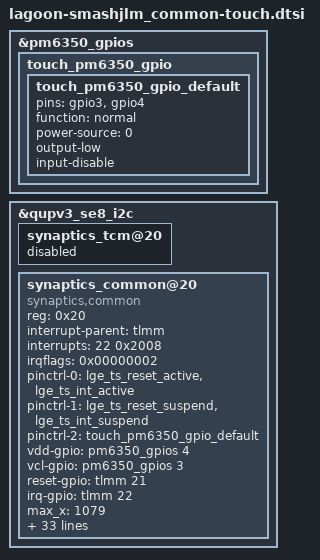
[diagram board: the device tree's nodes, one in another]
// SPDX-License-Identifier: GPL-2.0-only
/*
 * Copyright (c) 2018-2019, The Linux Foundation. All rights reserved.
 */

&pm6350_gpios {
	touch_pm6350_gpio{
		touch_pm6350_gpio_default: touch_pm6350_gpio_default {
			pins = "gpio3", "gpio4";
			function = "normal";
			power-source = <0>;
			output-low;
			input-disable;
		};
	};
};

&qupv3_se8_i2c {

	status = "okay";

	synaptics_tcm@20 {
		status = "disabled";
	};

	synaptics_common@20 {
		status = "ok";
		compatible = "synaptics,common";

		reg = <0x20>;
		interrupt-parent = <&tlmm>;
		interrupts = <22 0x2008>;
		irqflags = <0x00000002>;      // Falling-Edge Trigger
		//irqflags = <0x00000008>;        // Low-Level Trigger

		pinctrl-names = "touch_pin_active", "touch_pin_sleep", "touch_pm6350_gpio_default";
		pinctrl-0 = <&lge_ts_reset_active &lge_ts_int_active>;
		pinctrl-1 = <&lge_ts_reset_suspend &lge_ts_int_suspend>;
		pinctrl-2 = <&touch_pm6350_gpio_default>;

		vdd-gpio = <&pm6350_gpios 4 0x00>;
		vcl-gpio = <&pm6350_gpios 3 0x00>;
		reset-gpio = <&tlmm 21 0x00>;
		irq-gpio = <&tlmm 22 0x2008>;

		/* Caps */
		max_x = <1079>;
		max_y = <2339>;
		max_pressure = <0xff>;
		max_width_major = <2339>;
		max_width_minor = <2339>;
		max_orientation = <90>;
		max_id = <10>;
		hw_reset_delay = <200>;
		sw_reset_delay = <200>;

		/* Role */
		use_lpwg = <1>;
		use_lpwg_test = <1>;
		hide_coordinate = <1>;
		use_film_status = <1>;
		use_synaptics_touchcomm = <1>;

		/* Firmware */
		fw_image = "touch/smashjlm/main/tianma/PLG675-V0.25-PR3106505-s3618_DS6_60064119.img",
			 "touch/smashjlm/main/tovis/PLG674-V0.05-PR3005749-s3706b_BLV86_DS5.10.81.2_20064105.img",
			 "touch/smashjlm/main/tovis/PLG680-V1.05-PR3151223-s3706b_BLV86_DS5.10.81.2_20064185.img";
		panel_spec = "touch/smashjlm/main/tovis/mh2lm_synaptics_limit.txt";
		panel_spec_mfts_folder = "touch/smashjlm/main/tovis/mh2lm_synaptics_limit_mfts.txt";

		/* Performance Test */
		use_perf_test = <1>;
		test_delay = <8>;
		test_pressure = <50>;
		test_width = <100>;
		click_test_x = <180>;
		click_test_y = <756>;
		v_drag_test_x = <144>;
		v_drag_test_start_y = <1971>;
		v_drag_test_end_y = <1148>;
		h_drag_test_start_x = <1131>;
		h_drag_test_end_x = <308>;
		h_drag_test_y = <2184>;
	};
};

